# TLE984x register map
Vendor: Infineon Technologies AG; File version: 1.6
CPU: CM0 r0p0, little endian, no MPU, no FPU, 2 interrupt priority bits
Registers are 32-bit, read-write, no defined reset value unless marked. A register's access mark holds for its fields unless they carry their own. Offsets are from the block's base; [hi:lo] are bit positions; 'fields as' and 'values as' point back to an identical list.

## MF
Base 0x48018000
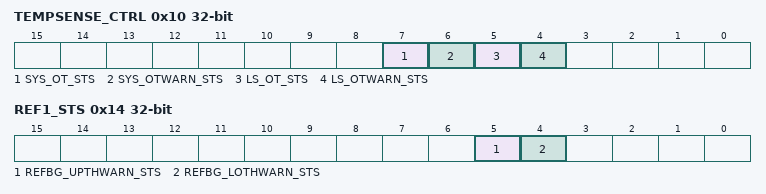
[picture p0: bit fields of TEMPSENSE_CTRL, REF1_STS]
0x10 TEMPSENSE_CTRL ro — Temperature Sensor Control Register
  [all] fields
    0=INACTIVE (write clears status); 1=ACTIVE (interrupt status set)
  [7] SYS_OT_STS — System Overtemperature (MU) Status
  [6] SYS_OTWARN_STS — System Overtemperature Warning (MU) Status
  [5] LS_OT_STS — Low Side Overtemperature (MU) Status
  [4] LS_OTWARN_STS — Low Side Overtemperature Warning (MU) Status
0x14 REF1_STS ro — Reference 1 Status Register
  [5] REFBG_UPTHWARN_STS — Status for Overvoltage Threshold Measurement of internal VAREF
    0=UPPER_TRIG_RESET (write clears status); 1=UPPER_TRIG_SET (trigger status set)
  [4] REFBG_LOTHWARN_STS — Status for Undervoltage Threshold Measurement of internal VAREF
    values as REFBG_UPTHWARN_STS

## SSC1
Base 0x48024000
Same registers: SSC2 0x48026000
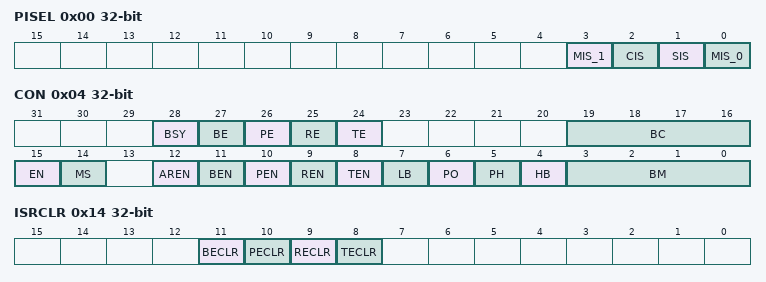
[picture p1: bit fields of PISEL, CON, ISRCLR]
0x00 PISEL — Port Input Select Register
  [3] MIS_1 — Master Mode Input Select Bit 1 (Master Mode only)
    0=Default (Inputs selected according to MIS_0.); 1=Do not use (Connects to unused pins.)
  [2] CIS — Clock Input Select (Slave Mode only)
    0=SSCx_S_SCK ((x = 1 or 2, dependant form current SSC), see .); 1=SSC12_S_SCK (for both SSCs. See .)
  [1] SIS — Slave Mode Input Select (Slave Mode only)
    0=SSCx_S_MTSR ((x = 1 or 2, dependant form current SSC), see .); 1=SSC12_S_MTSR (for both SSCs. See .)
  [0] MIS_0 — Master Mode Input Select Bit 0 (Master Mode only)
    0=SSCx_M_MRST ((x = 1 or 2, dependant form current SSC), see .); 1=SSC12_M_MRST (for both SSCs. See .)
0x04 CON access per field — Control Register
  [28] BSY ro — Busy Flag
  [27] BE ro — Baud Rate Error Flag
    0=NO (error.); 1=ERROR (More than factor 2 or 0.5 between slave's actual and expected baud rate.)
  [26] PE ro — Phase Error Flag
    0=NO (error.); 1=ERROR (Received data changes around sampling clock edge.)
  [25] RE ro — Receive Error Flag
    0=NO (error.); 1=ERROR (Reception completed before the receive buffer was read.)
  [24] TE ro — Transmit Error Flag
    0=NO (error.); 1=ERROR (Transfer starts with the slave's transmit buffer not being updated.)
  [19:16] BC ro — Bit Count Field
  [15] EN rw — Enable Bit
    0=Programming Mode (Transmission and reception disabled. Access to control bits.); 1=Operating Mode (Transmission and reception enabled. Access to status flags and M/S control.)
  [14] MS rw — Master Select
    0=SLAVE (Mode. Operate on shift clock received via SCLK.); 1=MASTER (Mode. Generate shift clock and output it via SCLK.)
  [12] AREN rw — Automatic Reset Enable
    0=N/A (No additional action upon a baud rate error.); 1=RESET (The SSC is automatically reset upon a baud rate error.)
  [11] BEN rw — Baud Rate Error Enable
    0=IGNORE (baud rate errors.); 1=CHECK (baud rate errors.)
  [10] PEN rw — Phase Error Enable
    0=IGNORE (phase errors.); 1=CHECK (phase errors.)
  [9] REN rw — Receive Error Enable
    0=IGNORE (receive errors.); 1=CHECK (receive errors.)
  [8] TEN rw — Transmit Error Enable
    0=IGNORE (transmit errors.); 1=CHECK (transmit errors.)
  [7] LB rw — Loop Back Control
    0=NORMAL (output.); 1=LB (Receive input is connected with transmit output (half-duplex mode).)
  [6] PO rw — Clock Polarity Control
    0=LOW (Idle clock line is low, leading clock edge is low-to-high transition.); 1=HIGH (Idle clock line is high, leading clock edge is high-to-low transition.)
  [5] PH rw — Clock Phase Control
    0=SHIFT (transmit data on the leading clock edge, latch on trailing edge.); 1=LATCH (receive data on leading clock edge, shift on trailing edge.)
  [4] HB rw — Heading Control
    0=LSB (Transmit/Receive LSB First.); 1=MSB (Transmit/Receive MSB First.)
  [3:0] BM rw — Data Width Selection
    0=Reserved. Do not use this combination.; 1=value2; 15=Transfer Data Width is 2 … 16 bits (BM+1)
0x08 TB — Transmitter Buffer Register
  [15:0] TB_VALUE — Transmit Data Register Value
0x0C RB ro — Receiver Buffer Register
  [15:0] RB_VALUE — Receive Data Register Value
0x10 BR — Baud Rate Timer Reload Register
  [15:0] BR_VALUE — Baud Rate Timer/Reload Register Value
0x14 ISRCLR wo — Interrupt Status Register Clear
  [all] fields
    0=NO (No error clear.); 1=CLEAR (Error clear.)
  [11] BECLR — Baud Rate Error Flag Clear
  [10] PECLR — Phase Error Flag Clear
  [9] RECLR — Receive Error Flag Clear
  [8] TECLR — Transmit Error Flag Clear
